# RL6842_IP_SVD register map
Vendor: Realtek
Registers are 32-bit, read-write, reset 0x0 unless marked. A register's access mark holds for its fields unless they carry their own. Offsets are from the block's base; [hi:lo] are bit positions.

## GPIO_REG
Base 0x4101A000
0x00 GPIO_DR — PortA/B data register
  [31:0] PORT_DATA — Values written to this register are output on the I/O signals for Portx if the corresponding data direction bits for Portx are set to Output mode and the corresponding control bit for Portx is set to software mode. The value read back is equal to the last value written to this register. Valid bits is: PortA[31:0] and PortB[19:0].
0x04 GPIO_DDR — PortA/B data direction register
  [31:0] PORT_DATA_DIRECTION — Values written to this register independently control the direction of the corresponding data bit in Portx. The default direction can be configured as input or output after system reset through the GPIO_DFLT_DIR_x parameter. 0: Input (default) 1: Output Valid bits is: PortA[31:0] and PortB[19:0].
0x30 GPIO_INT_EN — PortA/B interrupt enable register
  [31:0] GPIO_INT_EN — Allows each bit of Portx to be configured for interrupts. By default, the generation of interrupts is disabled. Whenever a 1 is written to a bit of this register, it configures the corresponding bit on Portx to become an interrupt; otherwise, Portx operates as a normal GPIO signal. Interrupts are disabled on the corresponding bits of Portx if the corresponding data direction register is set to Output or if Portx mode is set to Hardware. 0: Configure Portx bit as normal GPIO signal (default) 1: Configure Portx bit as interrupt
0x34 GPIO_INT_MASK — PortA/B interrupt mask register
  [31:0] GPIO_INT_MASK — Controls whether an interrupt on Portx can create an interrupt for the interrupt controller by not masking it. By default, all interrupts bits are unmasked. Whenever a 1 is written to a bit in this register, it masks the interrupt generation capability for this signal; otherwise interrupts are allowed through. The unmasked status can be read as well as the resultant status after masking. 0: Interrupt bits are unmasked (default) 1: Mask interrupt
0x38 GPIO_INT_TYPE — PortA interrupt trigger type register
  [31:0] GPIO_INT_TYPE — Controls the type of interrupt that can occur on Portx. Whenever a 0 is written to a bit of this register, it configures the interrupt type to be level-sensitive; otherwise, it is edge-sensitive. 0: Level-sensitive (default) 1: Edge-sensitive
0x3C GPIO_INT_POLARITY — PortA interrupt polarity register
  [31:0] GPIO_INT_POLARITY — Controls the polarity of edge or level sensitivity that can occur on input of Portx. Whenever a 0 is written to a bit of this register, it configures the interrupt type to falling-edge or active-low sensitive; otherwise, it is rising-edge or active-high sensitive. 0: Active-low (default) 1: Active-high
0x40 GPIO_INT_STATUS ro — PortA/B interrupt status register
  [31:0] GPIO_INT_STATUS — Interrupt status of Portx.
0x44 GPIO_INT_STATUS_RAW ro — PortA/B raw interrupt status register
  [31:0] GPIO_RAW_INT_STATUS — Raw interrupt status of Portx (premasking bits).
0x48 GPIO_DEBOUNCE — PortA/B interrupt debounce register
  [31:0] GPIO_DEBOUNCE_EN — Controls whether an external signal that is the source of an interrupt needs to be debounced to remove any spurious glitches. Writing a 1 to a bit in this register enables the debouncing circuitry. A signal must be valid for two periods of an external clock before it is internally processed. 0: No debounce (default) 1: Enable debounce This register is available only if Portx is configured to generate interrupts (GPIO_PORTA_INTR = Include (1)) and when the debounce logic is included (GPIO_DEBOUNCE = Include (1)).
0x4C GPIO_INT_EOI wo — PortA/B edge type interrupt clear register
  [31:0] GPIO_INT_EOI — Controls the clearing of edge type interrupts from Portx. When a 1 is written into a corresponding bit of this register, the interrupt is cleared. All interrupts are cleared when Portx is not configured for interrupts. 0: No interrupt clear (default) 1: Clear interrupt
0x50 GPIO_EXT_PORT ro — External PortA/B data register
  [31:0] GPIO_EXT_PORTA — When Portx is configured as Input, then reading this location reads the values on the signal. When the data direction of Portx is set as Output, reading this location reads the data register for Portx.
0x60 GPIO_ITN_LS_SYNC — PortA/B level interrupt synchronization
  [0] GPIO_Level_SYNC — Writing a 1 to this register results in all level-sensitive interrupts being synchronized to pclk_intr. 0: No synchronization to pclk_intr (default) 1: Synchronize to pclk_intr
0x64 GPIO_ID_CODE ro reset 0x1 — PortA/B GPIO ID code register
  [31:0] GPIO_ID_CODE — This register is available only if PortxA/B is configured to generate interrupts (GPIO_PORTx_INTR = Include (1)) and interrupt detection is configured to generate on both rising and falling edges of external input signal (GPIO_INT_BOTH_EDGE=Include (1)).
0x68 GPIO_INT_BOTHEDGE — PortA/B both edge interrupt register
  [31:0] GPIO_INT_BOTHEDGE — Controls the edge types of interrupt that can occur on Portx. Whenever a particular bit is programmed to 1, it enables the generation of interrupt on both the rising edge and falling edge of an external input signal corresponding to that bit on PortA. The values programmed in the registers gpio_intype_level and gpio_int_polarity for this particular bit are not considered when the corresponding bit of this register is set to 1. Whenever a particular bit is programmed to 0, the interrupt type depends on the value of the corresponding bits in the gpio_inttype_level and gpio_int_polarity registers. 0: Disabled. Single edge sensitive 1: Enabled. Both edge sensitive
0x6C GPIO_VER_ID_CODE ro reset 0x3231302A — PortA/B GPIO component version register
  [31:0] GPIO_VER_ID_CODE — ASCII value for each number in the version, followed by *. For example 32_30_31_2A represents the version 2.01*. Reset Value: See the releases table in the Release Notes.
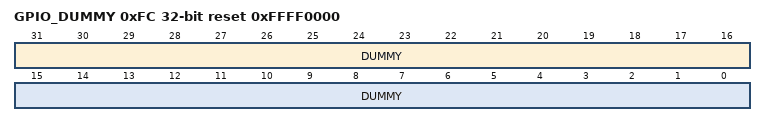
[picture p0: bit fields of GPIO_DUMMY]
0xFC GPIO_DUMMY reset 0xFFFF0000
  [31:16] DUMMY — No real reg, only for run_espec.py
  [15:0] DUMMY — No real reg, only for run_espec.py
